# FM33L0XXD register map
File version: 1.0
CPU: SC000 r1p0, little endian, no MPU, FPU, 8 interrupt priority bits
Registers are 32-bit, read-write, reset 0x0 unless marked. A register's access mark holds for its fields unless they carry their own. Offsets are from the block's base; [hi:lo] are bit positions; {n}, {i} and the like mark numbered series.

## EXTIM1 — EXTIM1 module information
Base 0x40013090
Same registers: EXTIM2 0x400130B0, EXTIM3 0x400130D0, EXTIM4 0x400130F0
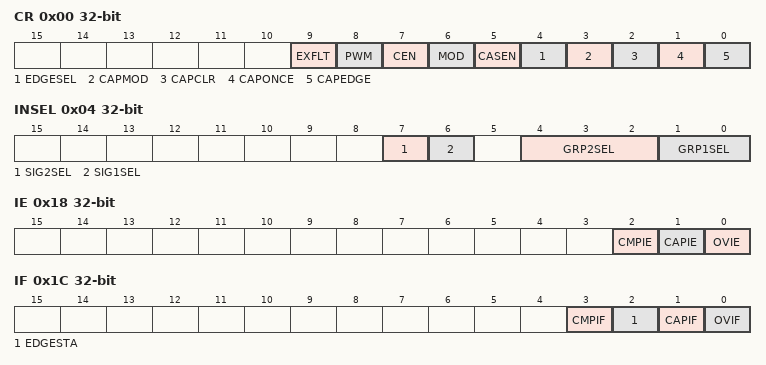
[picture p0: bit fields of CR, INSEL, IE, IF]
0x00 CR
  [9] EXFLT — EXFLT field description
  [8] PWM — PWM field description
  [7] CEN — CEN field description
  [6] MOD — MOD field description
  [5] CASEN — CASEN field description
  [4] EDGESEL — EDGESEL field description
  [3] CAPMOD — CAPMOD field description
  [2] CAPCLR — CAPCLR field description
  [1] CAPONCE — CAPONCE field description
  [0] CAPEDGE — CAPEDGE field description
0x04 INSEL
  [7] SIG2SEL — SIG2SEL field description
  [6] SIG1SEL — SIG1SEL field description
  [4:2] GRP2SEL — GRP2SEL field description
  [1:0] GRP1SEL — GRP1SEL field description
0x08 PRESCALE1
  [7:0] PRESCALE1 — PRESCALE1 field description
0x0C PRESCALE2
  [7:0] PRESCALE2 — PRESCALE2 field description
0x10 INITVALUE
  [15:0] INITVALUE — INITVALUE field description
0x14 CMP
  [15:0] CMP — CMP field description
0x18 IE
  [2] CMPIE — CMPIE field description
  [1] CAPIE — CAPIE field description
  [0] OVIE — OVIE field description
0x1C IF
  [3] CMPIF — CMPIF field description
  [2] EDGESTA — EDGESTA field description
  [1] CAPIF — CAPIF field description
  [0] OVIF — OVIF field description

## EXTIMCOM — EXTIMCOM module information
Base 0x40013110
0x00 ET1CNT
  [15:0] CNT ro — CNT field description
0x04 ET2CNT
  [15:0] CNT ro — CNT field description
0x08 ET3CNT
  [15:0] CNT ro — CNT field description
0x0C ET4CNT
  [15:0] CNT ro — CNT field description

## FLASH — FLASH module information
Base 0x40001000
0x00 RDCON
  [1:0] WAITSTATE — WAIT_STATE field description
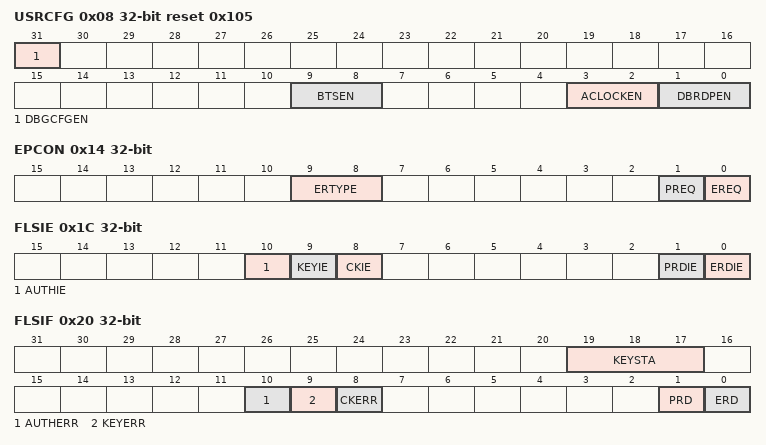
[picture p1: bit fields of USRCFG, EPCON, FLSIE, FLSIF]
0x08 USRCFG reset 0x105
  [31] DBGCFGEN ro — DBGCFGEN field description
  [9:8] BTSEN ro — BTSEN field description
  [3:2] ACLOCKEN ro — ACLOCKEN field description
  [1:0] DBRDPEN ro — DBRDPEN field description
0x0C ACLOCK1
  [31:0] ACLOCK — ACLOCK field description
0x14 EPCON
  [9:8] ERTYPE — ERTYPE field description
  [1] PREQ — PREQ field description
  [0] EREQ — EREQ field description
0x18 FLSKEY
  [31:0] FLSKEY wo — FLSKEY field description
0x1C FLSIE
  [10] AUTHIE — AUTHIE field description
  [9] KEYIE — KEYIE field description
  [8] CKIE — CKIE field description
  [1] PRDIE — PRDIE field description
  [0] ERDIE — ERDIE field description
0x20 FLSIF
  [19:17] KEYSTA ro — KEYSTA field description
  [10] AUTHERR — AUTHERR field description
  [9] KEYERR — KEYERR field description
  [8] CKERR — CKERR field description
  [1] PRD — PRD field description
  [0] ERD — ERD field description

## GPIOA — GPIOA module information
Base 0x40000C00
Same registers: GPIOB 0x40000C20, GPIOC 0x40000C40, GPIOD 0x40000C60, GPIOE 0x40000C80, GPIOF 0x40000CA0, GPIOG 0x40000CC0
0x00 INEN
  [15:0] INEN — INEN field description
0x04 PUEN
  [15:0] PUEN — PUEN field description
0x08 ODEN
  [15:0] ODEN — ODEN field description
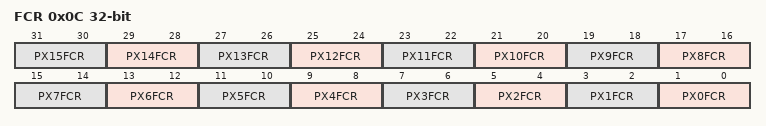
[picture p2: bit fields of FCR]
0x0C FCR
  [2n+1:2n] PX{n}FCR (n=0..15) — PX{n}FCR field description
0x10 DO
  [15:0] DO — DO field description
0x14 DSET
  [15:0] DSET wo — DSET field description
0x18 DRESET
  [15:0] DRESET wo — DRESET field description
0x1C DIN
  [15:0] DIN ro — DIN field description

## GPIO — GPIO module information
Base 0x40000CE0
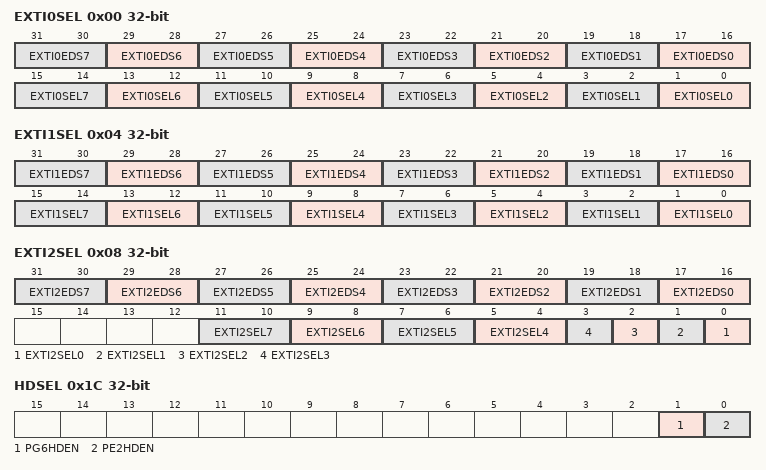
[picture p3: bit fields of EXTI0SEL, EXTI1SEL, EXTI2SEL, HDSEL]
0x00 EXTI0SEL
  [2n+17:2n+16] EXTI0EDS{n} (n=0..7) — EXTI0_EDS{n} field description
  [2n+1:2n] EXTI0SEL{n} (n=0..7) — EXTI0_SEL{n} field description
0x04 EXTI1SEL
  [2n+17:2n+16] EXTI1EDS{n} (n=0..7) — EXTI1_EDS{n} field description
  [2n+1:2n] EXTI1SEL{n} (n=0..7) — EXTI1_SEL{n} field description
0x08 EXTI2SEL
  [2n+17:2n+16] EXTI2EDS{n} (n=0..7) — EXTI2_EDS{n} field description
  [2n-3:2n-4] EXTI2SEL{n} (n=4..7) — EXTI2_SEL{n} field description
  [n] EXTI2SEL{n} (n=0..3) — EXTI2_SEL{n} field description
{0xC+4i} EXTI{i}IF (i=0..2)
  [7:0] EXTI{i}IF — EXTI{i}IF field description
0x18 FOUTSEL
  [3:0] FOUT0SEL — FOUT0SEL field description
0x1C HDSEL
  [1] PG6HDEN — PG6HDEN field description
  [0] PE2HDEN — PE2HDEN field description
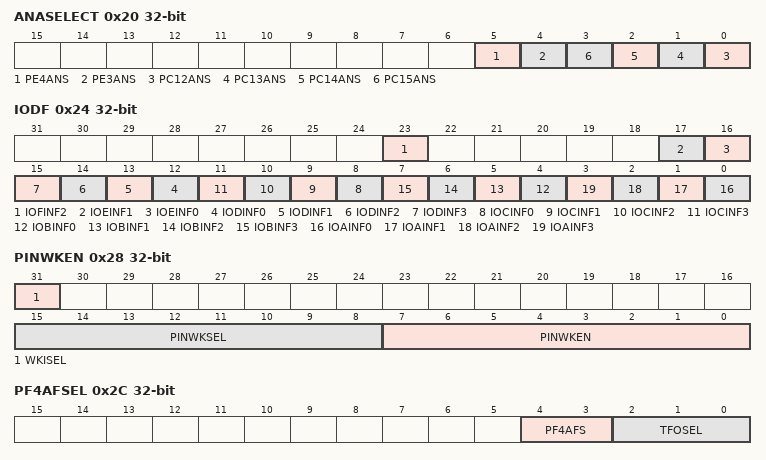
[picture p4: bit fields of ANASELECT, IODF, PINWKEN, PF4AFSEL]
0x20 ANASELECT
  [5] PE4ANS — PE4ANS field description
  [4] PE3ANS — PE3ANS field description
  [n-12] PC{n}ANS (n=12..15) — PC{n}ANS field description
0x24 IODF
  [23] IOFINF2 — IOFINF2 field description
  [17] IOEINF1 — IOEINF1 field description
  [16] IOEINF0 — IOEINF0 field description
  [n+12] IODINF{n} (n=0..3) — IODINF{n} field description
  [n+8] IOCINF{n} (n=0..3) — IOCINF{n} field description
  [n+4] IOBINF{n} (n=0..3) — IOBINF{n} field description
  [n] IOAINF{n} (n=0..3) — IOAINF{n} field description
0x28 PINWKEN
  [31] WKISEL — WKISEL field description
  [15:8] PINWKSEL — PINWKSEL field description
  [7:0] PINWKEN — PINWKEN field description
0x2C PF4AFSEL
  [4:3] PF4AFS — PF4AFS field description
  [2:0] TFOSEL — TFOSEL field description
